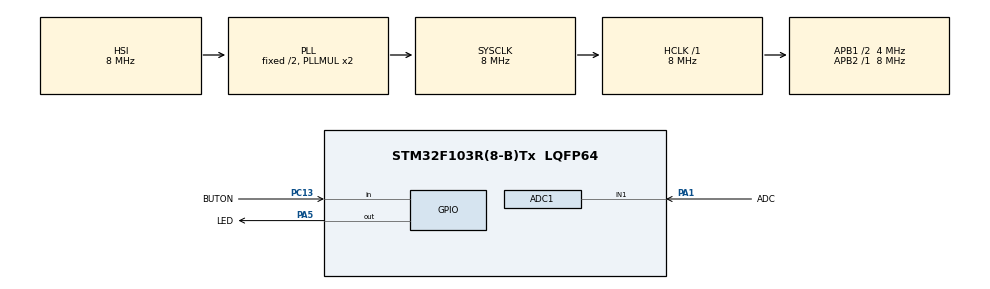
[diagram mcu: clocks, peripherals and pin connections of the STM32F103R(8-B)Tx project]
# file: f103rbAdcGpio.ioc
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Mcu.Family=STM32F1
PC15-OSC32_OUT.Mode=LSE-External-Oscillator
ADC1.Rank-0\#ChannelRegularConversion=1
PD1-OSC_OUT.Mode=HSE-External-Clock-Source
ADC1.ContinuousConvMode=ENABLE
PA14.GPIO_Label=TCK
PC13-TAMPER-RTC.Signal=GPIO_Input
PD0-OSC_IN.Signal=RCC_OSC_IN
RCC.APB1CLKDivider=RCC_HCLK_DIV2
PC14-OSC32_IN.Signal=RCC_OSC32_IN
RCC.SYSCLKSource=RCC_SYSCLKSOURCE_PLLCLK
ProjectManager.StackSize=0x400
PD1-OSC_OUT.Signal=RCC_OSC_OUT
PA13.Signal=SYS_JTMS-SWDIO
ProjectManager.TargetToolchain=STM32CubeIDE
RCC.HCLKFreq_Value=8000000
RCC.APB2TimFreq_Value=8000000
RCC.USBFreq_Value=8000000
PC15-OSC32_OUT.Signal=RCC_OSC32_OUT
PA1.Signal=ADCx_IN1
RCC.AHBFreq_Value=8000000
PD0-OSC_IN.Mode=HSE-External-Clock-Source
PA5.Signal=GPIO_Output
ADC1.Channel-0\#ChannelRegularConversion=ADC_CHANNEL_1
board=NUCLEO-F103RB
RCC.RTCClockSelection=RCC_RTCCLKSOURCE_LSE
PC13-TAMPER-RTC.GPIO_Label=BUTON
RCC.APB2Freq_Value=8000000
PC14-OSC32_IN.Mode=LSE-External-Oscillator
PA5.GPIO_ModeDefaultOutputPP=GPIO_MODE_OUTPUT_PP
PA14.Mode=Serial_Wire
PA5.GPIO_PuPd=GPIO_NOPULL
PA1.GPIO_Label=ADC
PA13.Mode=Serial_Wire
Mcu.Name=STM32F103R(8-B)Tx
ADC1.SamplingTime-0\#ChannelRegularConversion=ADC_SAMPLETIME_1CYCLE_5
PA13.GPIO_Label=TMS
RCC.SYSCLKFreq_VALUE=8000000
Mcu.Package=LQFP64
ADC1.master=1
PA5.GPIO_Label=LED
PA14.Signal=SYS_JTCK-SWCLK
ProjectManager.HeapSize=0x200
PA5.GPIO_Speed=GPIO_SPEED_FREQ_LOW
NVIC.PriorityGroup=NVIC_PRIORITYGROUP_4
ADC1.NbrOfConversionFlag=1
SH.ADCx_IN1.0=ADC1_IN1,IN1
RCC.APB1TimFreq_Value=8000000
RCC.APB1Freq_Value=4000000

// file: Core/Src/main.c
/* USER CODE BEGIN Header */
/**
  ******************************************************************************
  * @file           : main.c
  * @brief          : Main program body
  ******************************************************************************
  * @attention
  *
  * <h2><center>&copy; Copyright (c) 2020 STMicroelectronics.
  * All rights reserved.</center></h2>
  *
  * This software component is licensed by ST under BSD 3-Clause license,
  * the "License"; You may not use this file except in compliance with the
  * License. You may obtain a copy of the License at:
  *                        opensource.org/licenses/BSD-3-Clause
  *
  ******************************************************************************
  */
/* USER CODE END Header */
#include "main.h"

ADC_HandleTypeDef hadc1;

void SystemClock_Config(void);
static void MX_GPIO_Init(void);
static void MX_ADC1_Init(void);
/* USER CODE BEGIN PFP */
int durum,start;
uint16_t adc;
/* USER CODE END PFP */

int main(void)
{

  /* MCU Configuration--------------------------------------------------------*/

  /* Reset of all peripherals, Initializes the Flash interface and the Systick. */
  HAL_Init();

  /* Configure the system clock */
  SystemClock_Config();

  /* Initialize all configured peripherals */
  MX_GPIO_Init();
  MX_ADC1_Init();

  /* Infinite loop */
  /* USER CODE BEGIN WHILE */
  while (1)
  {
	  if(!HAL_GPIO_ReadPin(BUTON_GPIO_Port, BUTON_Pin))
	  {
		  HAL_Delay(100);
		  if(!HAL_GPIO_ReadPin(BUTON_GPIO_Port, BUTON_Pin))
		  {
			  durum=1;
		  }
	  }

	  if(durum)
	  {
		  if(start)
		  {
			  start=0;
			  HAL_ADC_Stop(&hadc1);
			  adc=0;
			  durum=0;
		  }
		  else
		  {
			  start=1;
			  HAL_ADC_Start(&hadc1);
			  durum=0;
		  }
	  }

	  if(start)
	  {
		  adc=HAL_ADC_GetValue(&hadc1);
	  }
    /* USER CODE END WHILE */

  }
}

void SystemClock_Config(void)
{
  RCC_OscInitTypeDef RCC_OscInitStruct = {0};
  RCC_ClkInitTypeDef RCC_ClkInitStruct = {0};
  RCC_PeriphCLKInitTypeDef PeriphClkInit = {0};

  /** Initializes the RCC Oscillators according to the specified parameters
  * in the RCC_OscInitTypeDef structure.
  */
  RCC_OscInitStruct.OscillatorType = RCC_OSCILLATORTYPE_HSI;
  RCC_OscInitStruct.HSIState = RCC_HSI_ON;
  RCC_OscInitStruct.HSICalibrationValue = RCC_HSICALIBRATION_DEFAULT;
  RCC_OscInitStruct.PLL.PLLState = RCC_PLL_ON;
  RCC_OscInitStruct.PLL.PLLSource = RCC_PLLSOURCE_HSI_DIV2;
  RCC_OscInitStruct.PLL.PLLMUL = RCC_PLL_MUL2;
  if (HAL_RCC_OscConfig(&RCC_OscInitStruct) != HAL_OK)
  {
    Error_Handler();
  }
  /** Initializes the CPU, AHB and APB buses clocks
  */
  RCC_ClkInitStruct.ClockType = RCC_CLOCKTYPE_HCLK|RCC_CLOCKTYPE_SYSCLK
                              |RCC_CLOCKTYPE_PCLK1|RCC_CLOCKTYPE_PCLK2;
  RCC_ClkInitStruct.SYSCLKSource = RCC_SYSCLKSOURCE_PLLCLK;
  RCC_ClkInitStruct.AHBCLKDivider = RCC_SYSCLK_DIV1;
  RCC_ClkInitStruct.APB1CLKDivider = RCC_HCLK_DIV2;
  RCC_ClkInitStruct.APB2CLKDivider = RCC_HCLK_DIV1;

  if (HAL_RCC_ClockConfig(&RCC_ClkInitStruct, FLASH_LATENCY_0) != HAL_OK)
  {
    Error_Handler();
  }
  PeriphClkInit.PeriphClockSelection = RCC_PERIPHCLK_ADC;
  PeriphClkInit.AdcClockSelection = RCC_ADCPCLK2_DIV2;
  if (HAL_RCCEx_PeriphCLKConfig(&PeriphClkInit) != HAL_OK)
  {
    Error_Handler();
  }
}

static void MX_ADC1_Init(void)
{

  ADC_ChannelConfTypeDef sConfig = {0};

  /** Common config
  */
  hadc1.Instance = ADC1;
  hadc1.Init.ScanConvMode = ADC_SCAN_DISABLE;
  hadc1.Init.ContinuousConvMode = ENABLE;
  hadc1.Init.DiscontinuousConvMode = DISABLE;
  hadc1.Init.ExternalTrigConv = ADC_SOFTWARE_START;
  hadc1.Init.DataAlign = ADC_DATAALIGN_RIGHT;
  hadc1.Init.NbrOfConversion = 1;
  if (HAL_ADC_Init(&hadc1) != HAL_OK)
  {
    Error_Handler();
  }
  /** Configure Regular Channel
  */
  sConfig.Channel = ADC_CHANNEL_1;
  sConfig.Rank = ADC_REGULAR_RANK_1;
  sConfig.SamplingTime = ADC_SAMPLETIME_1CYCLE_5;
  if (HAL_ADC_ConfigChannel(&hadc1, &sConfig) != HAL_OK)
  {
    Error_Handler();
  }

}

static void MX_GPIO_Init(void)
{
  GPIO_InitTypeDef GPIO_InitStruct = {0};

  /* GPIO Ports Clock Enable */
  __HAL_RCC_GPIOC_CLK_ENABLE();
  __HAL_RCC_GPIOD_CLK_ENABLE();
  __HAL_RCC_GPIOA_CLK_ENABLE();

  /*Configure GPIO pin Output Level */
  HAL_GPIO_WritePin(LED_GPIO_Port, LED_Pin, GPIO_PIN_RESET);

  /*Configure GPIO pin : BUTON_Pin */
  GPIO_InitStruct.Pin = BUTON_Pin;
  GPIO_InitStruct.Mode = GPIO_MODE_INPUT;
  GPIO_InitStruct.Pull = GPIO_NOPULL;
  HAL_GPIO_Init(BUTON_GPIO_Port, &GPIO_InitStruct);

  /*Configure GPIO pin : LED_Pin */
  GPIO_InitStruct.Pin = LED_Pin;
  GPIO_InitStruct.Mode = GPIO_MODE_OUTPUT_PP;
  GPIO_InitStruct.Pull = GPIO_NOPULL;
  GPIO_InitStruct.Speed = GPIO_SPEED_FREQ_LOW;
  HAL_GPIO_Init(LED_GPIO_Port, &GPIO_InitStruct);

}

void Error_Handler(void)
{
  __disable_irq();
  while (1)
  {
  }
}

/************************ (C) COPYRIGHT STMicroelectronics *****END OF FILE****/
